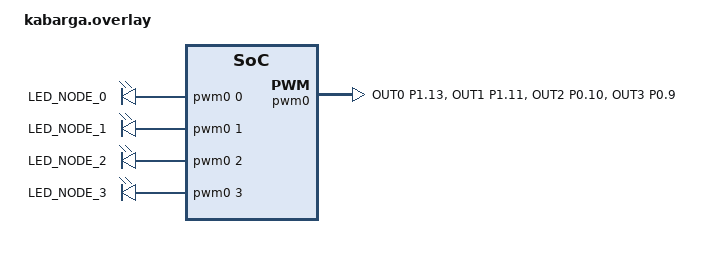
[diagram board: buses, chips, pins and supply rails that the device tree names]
/*
 * Copyright (c) 2020 The ZMK Contributors
 *
 * SPDX-License-Identifier: MIT
 */

#include "kabarga.dtsi"
/ {
    backlight: pwmleds {
        compatible = "pwm-leds";
        pwm_led_0: led_0 {
            pwms = <&pwm0 0 PWM_MSEC(10) PWM_POLARITY_NORMAL>;
            label = "LED_NODE_0";
        };
        pwm_led_1: led_1 {
            pwms = <&pwm0 1 PWM_MSEC(10) PWM_POLARITY_NORMAL>;
            label = "LED_NODE_1";
        };
        pwm_led_2: led_2 {
            label = "LED_NODE_2";
            pwms = <&pwm0 2 PWM_MSEC(10) PWM_POLARITY_NORMAL>;
        };
        pwm_led_3: led_3 {
            pwms = <&pwm0 3 PWM_MSEC(10) PWM_POLARITY_NORMAL>;
            label = "LED_NODE_3";
        };
    };
};
&pwm0 {
    status = "okay";
    pinctrl-0 = <&pwm0_default>;
    pinctrl-1 = <&pwm0_sleep>;
    pinctrl-names = "default", "sleep";
};
&pinctrl {
    // Other Pinctrl definitions go here
    pwm0_default: pwm0_default {
        group1 {
            psels = <NRF_PSEL(PWM_OUT0, 1, 13)>, // LED 0
                    <NRF_PSEL(PWM_OUT1, 1, 11)>, // LED 1
                    <NRF_PSEL(PWM_OUT2, 0, 10)>, // LED 2
                    <NRF_PSEL(PWM_OUT3, 0, 9)>;  // LED 3
        };
    };
    pwm0_sleep: pwm0_sleep {
        group1 {
            psels = <NRF_PSEL(PWM_OUT0, 1, 13)>, // LED 0
                    <NRF_PSEL(PWM_OUT1, 1, 11)>, // LED 1
                    <NRF_PSEL(PWM_OUT2, 0, 10)>, // LED 2
                    <NRF_PSEL(PWM_OUT3, 0, 9)>;  // LED 3
            low-power-enable;
        };
    };
};
&pwm0 {
    status = "okay";
    pinctrl-0 = <&pwm0_default>;
    pinctrl-1 = <&pwm0_sleep>;
    pinctrl-names = "default", "sleep";
};
